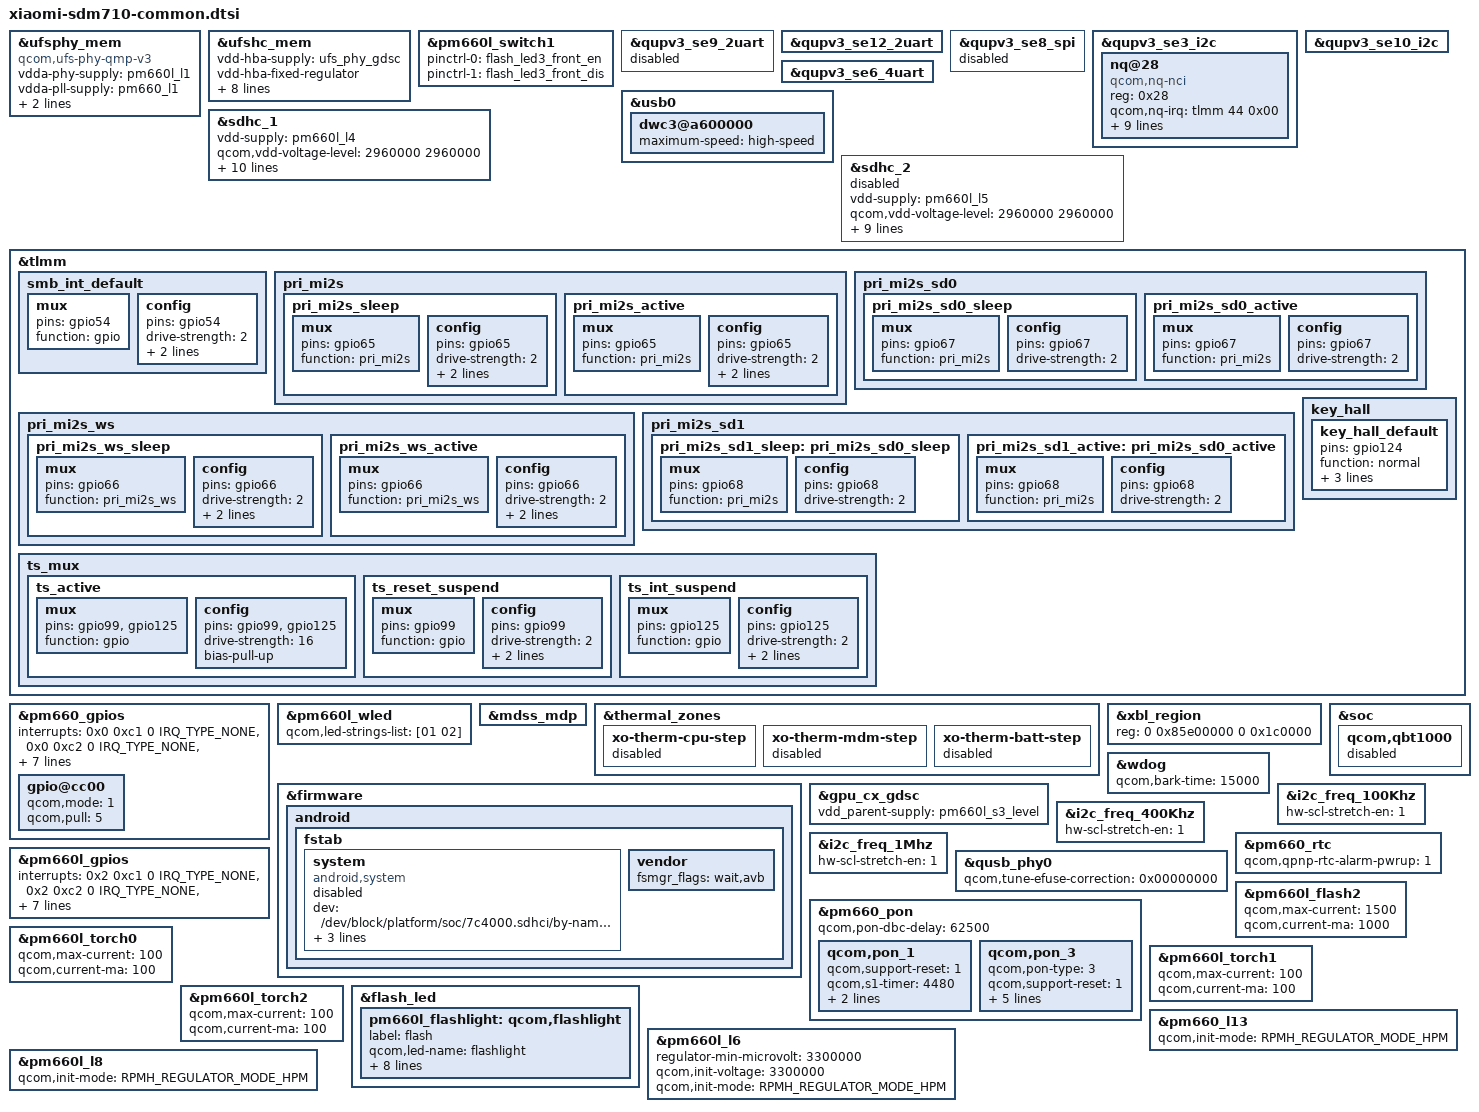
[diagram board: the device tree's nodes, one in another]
/* Copyright (c) 2017, The Linux Foundation. All rights reserved.
 * Copyright (C) 2020 XiaoMi, Inc.
 *
 * This program is free software; you can redistribute it and/or modify
 * it under the terms of the GNU General Public License version 2 and
 * only version 2 as published by the Free Software Foundation.
 *
 * This program is distributed in the hope that it will be useful,
 * but WITHOUT ANY WARRANTY; without even the implied warranty of
 * MERCHANTABILITY or FITNESS FOR A PARTICULAR PURPOSE.  See the
 * GNU General Public License for more details.
 */

#include <dt-bindings/gpio/gpio.h>
#include "sdm670-pmic-overlay.dtsi"
#include "xiaomi-sde-display.dtsi"

&ufsphy_mem {
	compatible = "qcom,ufs-phy-qmp-v3";

	vdda-phy-supply = <&pm660l_l1>; /* 0.88v */
	vdda-pll-supply = <&pm660_l1>; /* 1.2v */
	vdda-phy-max-microamp = <62900>;
	vdda-pll-max-microamp = <18300>;

	status = "ok";
};

&ufshc_mem {
	vdd-hba-supply = <&ufs_phy_gdsc>;
	vdd-hba-fixed-regulator;
	vcc-supply = <&pm660l_l4>;
	vcc-voltage-level = <2960000 2960000>;
	vccq2-supply = <&pm660_l8>;
	vcc-max-microamp = <600000>;
	vccq2-max-microamp = <600000>;

	qcom,vddp-ref-clk-supply = <&pm660_l1>;
	qcom,vddp-ref-clk-max-microamp = <100>;

	status = "ok";
};

&pm660l_switch1 {
	pinctrl-names = "led_enable", "led_disable";
	pinctrl-0 = <&flash_led3_front_en>;
	pinctrl-1 = <&flash_led3_front_dis>;
};

&qupv3_se9_2uart {
	status = "disabled";
};

&qupv3_se12_2uart {
	status = "ok";
};

&qupv3_se8_spi {
	status = "disabled";
};

&qupv3_se3_i2c {
	status = "ok";
	nq@28 {
		compatible = "qcom,nq-nci";
		reg = <0x28>;
		qcom,nq-irq = <&tlmm 44 0x00>;
		qcom,nq-ven = <&tlmm 12 0x00>;
		qcom,nq-firm = <&tlmm 43 0x00>;
		qcom,nq-clkreq = <&pm660_gpios 4 0x00>;
		qcom,nq-esepwr = <&tlmm 116 0x00>;
		interrupt-parent = <&tlmm>;
		interrupts = <44 0>;
		interrupt-names = "nfc_irq";
		pinctrl-names = "nfc_active", "nfc_suspend","default";
		pinctrl-0 = <&nfc_int_active &nfc_enable_active>;
		pinctrl-1 = <&nfc_int_suspend &nfc_enable_suspend>;
		pinctrl-2 = <&nfc_clk_default>;
	};
};

&qupv3_se10_i2c {
	status = "ok";
};

&qupv3_se6_4uart {
	status = "ok";
};

&usb0 {
	dwc3@a600000 {
		maximum-speed = "high-speed";
	};
};

&sdhc_1 {
	vdd-supply = <&pm660l_l4>;
	qcom,vdd-voltage-level = <2960000 2960000>;
	qcom,vdd-current-level = <0 570000>;

	vdd-io-supply = <&pm660_l8>;
	qcom,vdd-io-always-on;
	qcom,vdd-io-lpm-sup;
	qcom,vdd-io-voltage-level = <1800000 1800000>;
	qcom,vdd-io-current-level = <0 325000>;

	pinctrl-names = "active", "sleep";
	pinctrl-0 = <&sdc1_clk_on  &sdc1_cmd_on &sdc1_data_on &sdc1_rclk_on>;
	pinctrl-1 = <&sdc1_clk_off &sdc1_cmd_off &sdc1_data_off &sdc1_rclk_off>;

	status = "ok";
};

&sdhc_2 {
	vdd-supply = <&pm660l_l5>;
	qcom,vdd-voltage-level = <2960000 2960000>;
	qcom,vdd-current-level = <0 800000>;

	vdd-io-supply = <&pm660l_l2>;
	qcom,vdd-io-voltage-level = <1800000 2960000>;
	qcom,vdd-io-current-level = <0 22000>;

	pinctrl-names = "active", "sleep";
	pinctrl-0 = <&sdc2_clk_on &sdc2_cmd_on &sdc2_data_on &sdc2_cd_on>;
	pinctrl-1 = <&sdc2_clk_off &sdc2_cmd_off &sdc2_data_off &sdc2_cd_off>;

	cd-gpios = <&tlmm 96 0x1>;

	status = "disable";
};

&tlmm {
	smb_int_default: smb_int_default {
		mux {
			pins = "gpio54";
			function = "gpio";
		};
		config {
			pins = "gpio54";
			drive-strength = <2>;
			bias-pull-up;
			input-enable;
		};
	};
};

&pm660_gpios {
	/* GPIO 13 (AUDIO_SEL) */
	gpio@cc00 {
		status = "okay";
		qcom,mode = <1>;    /* Digital out */
		qcom,pull = <5>;    /* No pull */
		/* qcom,vin-sel = <1>;*/ /* 1.8v */
		/*
		  qcom,src-sel = <0>;
		  qcom,out-strength = <1>;
		  qcom,master-en = <1>;
		  qcom,invert = <1>;
		*/
	};
};

&pm660l_wled {
	status = "okay";
	qcom,led-strings-list = [01 02];
};

&mdss_mdp {
	#cooling-cells = <2>;
};

&thermal_zones {
	xo-therm-cpu-step {
		status = "disabled";
	};
	xo-therm-mdm-step {
		status = "disabled";
	};
	xo-therm-batt-step {
		status = "disabled";
	};
};

/* sdm670.dtsi */
&firmware {
	android {
		fstab {
			system {
				compatible = "android,system";
				dev = "/dev/block/platform/soc/7c4000.sdhci/by-name/system";
				type = "ext4";
				mnt_flags = "ro,barrier=1,discard";
				fsmgr_flags = "wait,avb";
				/* originally enabled, but only sirius has early mount */
				status = "disabled";
			};

			vendor {
				fsmgr_flags = "wait,avb";
			};
		};
	};
};

&xbl_region {
	reg = <0 0x85e00000 0 0x1c0000>;
};

&soc {
	qcom,qbt1000 {
		status = "disabled";
	};
};

&wdog {
	qcom,bark-time = <15000>;
};

&ufshc_mem {
	spm-level = <3>;
};

&gpu_cx_gdsc {
	vdd_parent-supply = <&pm660l_s3_level>;
};

/* sdm670-pinctrl.dtsi */
&tlmm {
	pri_mi2s {
		pri_mi2s_sleep: pri_mi2s_sleep {
			mux {
				pins = "gpio65";
				function = "pri_mi2s";
			};

			config {
				pins = "gpio65";
				drive-strength = <2>; /* 2 mA */
				bias-pull-down; /* PULL DOWN */
				input-enable;
			};
		};

		pri_mi2s_active: pri_mi2s_active {
			mux {
				pins = "gpio65";
				function = "pri_mi2s";
			};

			config {
				pins = "gpio65";
				drive-strength = <2>; /* 2 mA */
				bias-disable; /* NO PULL */
				output-high;
			};
		};
	};

	pri_mi2s_ws {
		pri_mi2s_ws_sleep: pri_mi2s_ws_sleep {
			mux {
				pins = "gpio66";
				function = "pri_mi2s_ws";
			};

			config {
				pins = "gpio66";
				drive-strength = <2>; /* 2 mA */
				bias-pull-down; /* PULL DOWN */
				input-enable;
			};
		};

		pri_mi2s_ws_active: pri_mi2s_ws_active {
			mux {
				pins = "gpio66";
				function = "pri_mi2s_ws";
			};

			config {
				pins = "gpio66";
				drive-strength = <2>; /* 2 mA */
				bias-disable; /* NO PULL */
				output-high;
			};
		};
	};

	pri_mi2s_sd0 {
		pri_mi2s_sd0_sleep: pri_mi2s_sd0_sleep {
			mux {
				pins = "gpio67";
				function = "pri_mi2s";
			};

			config {
				pins = "gpio67";
				drive-strength = <2>; /* 2 mA */
			};
		};

		pri_mi2s_sd0_active: pri_mi2s_sd0_active {
			mux {
				pins = "gpio67";
				function = "pri_mi2s";
			};

			config {
				pins = "gpio67";
				drive-strength = <2>; /* 2 mA */
			};
		};
	};

	pri_mi2s_sd1 {
		pri_mi2s_sd1_sleep: pri_mi2s_sd0_sleep {
			mux {
				pins = "gpio68";
				function = "pri_mi2s";
			};

			config {
				pins = "gpio68";
				drive-strength = <2>; /* 2 mA */
			};
		};

		pri_mi2s_sd1_active: pri_mi2s_sd0_active {
			mux {
				pins = "gpio68";
				function = "pri_mi2s";
			};

			config {
				pins = "gpio68";
				drive-strength = <2>; /* 2 mA */
			};
		};
	};

	key_hall {
		key_hall_default: key_hall_default {
			pins = "gpio124";
			function = "normal";
			input-enable;
			bias-pull-up;
			power-source = <0>;
		};
	};

	ts_mux {
		ts_active: ts_active {
			mux {
				pins = "gpio99", "gpio125";
				function = "gpio";
			};

			config {
				pins = "gpio99", "gpio125";
				drive-strength = <16>;
				bias-pull-up;
			};
		};

		ts_reset_suspend: ts_reset_suspend {
			mux {
				pins = "gpio99";
				function = "gpio";
			};

			config {
				pins = "gpio99";
				drive-strength = <2>;
				bias-disable;
				input-enable;
			};
		};

		ts_int_suspend: ts_int_suspend {
			mux {
				pins = "gpio125";
				function = "gpio";
			};

			config {
				pins = "gpio125";
				drive-strength = <2>;
				bias-disable;
				input-enable;
			};
		};
	};
};

/* sdm670-camera.dtsi */
&i2c_freq_100Khz {
	hw-scl-stretch-en = <1>;
};

&i2c_freq_400Khz {
	hw-scl-stretch-en = <1>;
};

&i2c_freq_1Mhz {
	hw-scl-stretch-en = <1>;
};

/* sdm845-670-usb-common.dtsi */
&qusb_phy0 {
	/* you can adjust this from 0xffff, fff9(-7) to 0x0000,0007(+7), 80-P6348-5D */
	qcom,tune-efuse-correction = <0x00000000>;
};

/* pm660.dtsi */
#include <dt-bindings/msm/power-on.h>

&pm660_pon {
	qcom,pon-dbc-delay = <62500>;

	qcom,pon_1 {
		qcom,support-reset = <1>;
		qcom,s1-timer = <4480>;
		qcom,s2-timer = <2000>;
		qcom,s2-type = <PON_POWER_OFF_HARD_RESET>;
	};

	qcom,pon_3 {
		qcom,pon-type = <3>;
		qcom,support-reset = <1>;
		qcom,pull-up = <1>;
		qcom,s1-timer = <1352>;
		qcom,s2-timer = <2000>;
		qcom,s2-type = <PON_POWER_OFF_WARM_RESET>;
		qcom,use-bark;
	};
};

&pm660_gpios {
	interrupts = <0x0 0xc1 0 IRQ_TYPE_NONE>,
			<0x0 0xc2 0 IRQ_TYPE_NONE>,
			<0x0 0xc3 0 IRQ_TYPE_NONE>,
			<0x0 0xc5 0 IRQ_TYPE_NONE>,
			<0x0 0xc8 0 IRQ_TYPE_NONE>,
			<0x0 0xca 0 IRQ_TYPE_NONE>,
			<0x0 0xcb 0 IRQ_TYPE_NONE>,
			<0x0 0xcc 0 IRQ_TYPE_NONE>;
	interrupt-names = "pm660_gpio2", "pm660_gpio3",
			"pm660_gpio4", "pm660_gpio6",
			"pm660_gpio9", "pm660_gpio11",
			"pm660_gpio12", "pm660_gpio13";
	qcom,gpios-disallowed = <1 5 7 8 10>;
};

&pm660_rtc {
	qcom,qpnp-rtc-alarm-pwrup = <1>;
};

/* pm660l.dtsi */
&pm660l_gpios {
	interrupts = <0x2 0xc1 0 IRQ_TYPE_NONE>,
			<0x2 0xc2 0 IRQ_TYPE_NONE>,
			<0x2 0xc3 0 IRQ_TYPE_NONE>,
			<0x2 0xc4 0 IRQ_TYPE_NONE>,
			<0x2 0xc5 0 IRQ_TYPE_NONE>,
			<0x2 0xc6 0 IRQ_TYPE_NONE>,
			<0x2 0xc7 0 IRQ_TYPE_NONE>,
			<0x2 0xc8 0 IRQ_TYPE_NONE>;
	interrupt-names = "pm660l_gpio2","pm660l_gpio3", "pm660l_gpio4",
			"pm660l_gpio5", "pm660l_gpio6",
			"pm660l_gpio7", "pm660l_gpio8",
			"pm660l_gpio9";
	qcom,gpios-disallowed = <1 10 11 12>;
};

&pm660l_flash2 {
	qcom,max-current = <1500>;
	qcom,current-ma = <1000>;
};

&pm660l_torch0 {
	qcom,max-current = <100>;
	qcom,current-ma = <100>;
};

&pm660l_torch1 {
	qcom,max-current = <100>;
	qcom,current-ma = <100>;
};

&pm660l_torch2 {
	qcom,max-current = <100>;
	qcom,current-ma = <100>;
};

&flash_led {
	pm660l_flashlight: qcom,flashlight {
		label = "flash";
		qcom,led-name = "flashlight";
		qcom,max-current = <750>;
		qcom,default-led-trigger = "flashlight_trigger";
		qcom,id = <3>;
		qcom,current-ma = <500>;
		qcom,duration-ms = <1280>;
		qcom,ires-ua = <12500>;
		qcom,hdrm-voltage-mv = <325>;
		qcom,hdrm-vol-hi-lo-win-mv = <100>;
	};
};

/* sdm670-regulator.dtsi */
#include <dt-bindings/regulator/qcom,rpmh-regulator.h>

&pm660_l13 {
	qcom,init-mode = <RPMH_REGULATOR_MODE_HPM>;
};

&pm660l_l6 {
	regulator-min-microvolt = <3300000>;
	qcom,init-voltage = <3300000>;
	qcom,init-mode = <RPMH_REGULATOR_MODE_HPM>;
};

&pm660l_l8 {
	qcom,init-mode = <RPMH_REGULATOR_MODE_HPM>;
};
